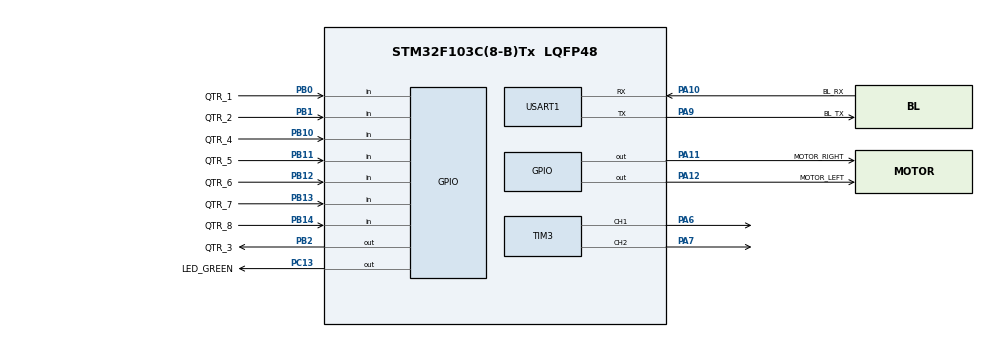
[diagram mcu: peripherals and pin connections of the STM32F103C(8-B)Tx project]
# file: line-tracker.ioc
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Mcu.Family=STM32F1
Mcu.Name=STM32F103C(8-B)Tx
Mcu.Package=LQFP48
NVIC.PriorityGroup=NVIC_PRIORITYGROUP_4
NVIC.TIM2_IRQn=true\:0\:0\:false\:false\:true\:true\:true
PA10.GPIO_Label=BL_RX
PA10.Mode=Asynchronous
PA10.Signal=USART1_RX
PA11.GPIO_Label=MOTOR_RIGHT
PA11.Signal=GPIO_Output
PA12.GPIO_Label=MOTOR_LEFT
PA12.Signal=GPIO_Output
PA13.Mode=Serial_Wire
PA13.Signal=SYS_JTMS-SWDIO
PA14.Mode=Serial_Wire
PA14.Signal=SYS_JTCK-SWCLK
PA6.Signal=S_TIM3_CH1
PA7.Signal=S_TIM3_CH2
PA9.GPIO_Label=BL_TX
PA9.Mode=Asynchronous
PA9.Signal=USART1_TX
PB0.GPIO_Label=QTR_1
PB0.Signal=GPIO_Input
PB1.GPIO_Label=QTR_2
PB1.Signal=GPIO_Input
PB10.GPIO_Label=QTR_4
PB10.Signal=GPIO_Input
PB11.GPIO_Label=QTR_5
PB11.Signal=GPIO_Input
PB12.GPIO_Label=QTR_6
PB12.Signal=GPIO_Input
PB13.GPIO_Label=QTR_7
PB13.Signal=GPIO_Input
PB14.GPIO_Label=QTR_8
PB14.Signal=GPIO_Input
PB2.GPIO_Label=QTR_3
PB2.Signal=GPIO_Output
PC13-TAMPER-RTC.GPIO_Label=LED_GREEN
PC13-TAMPER-RTC.Signal=GPIO_Output
PC14-OSC32_IN.Mode=LSE-External-Oscillator
PC14-OSC32_IN.Signal=RCC_OSC32_IN
PC15-OSC32_OUT.Mode=LSE-External-Oscillator
PC15-OSC32_OUT.Signal=RCC_OSC32_OUT
PD0-OSC_IN.Mode=HSE-External-Oscillator
PD0-OSC_IN.Signal=RCC_OSC_IN
PD1-OSC_OUT.Mode=HSE-External-Oscillator
PD1-OSC_OUT.Signal=RCC_OSC_OUT
ProjectManager.HeapSize=0x0
ProjectManager.StackSize=0x400
ProjectManager.TargetToolchain=TrueSTUDIO
RCC.AHBFreq_Value=72000000
RCC.APB1CLKDivider=RCC_HCLK_DIV2
RCC.APB1Freq_Value=36000000
RCC.APB1TimFreq_Value=72000000
RCC.APB2Freq_Value=72000000
RCC.APB2TimFreq_Value=72000000
RCC.HCLKFreq_Value=72000000
RCC.PLLMUL=RCC_PLL_MUL9
RCC.PLLSourceVirtual=RCC_PLLSOURCE_HSE
RCC.SYSCLKFreq_VALUE=72000000
RCC.SYSCLKSource=RCC_SYSCLKSOURCE_PLLCLK
RCC.USBFreq_Value=72000000
SH.S_TIM3_CH1.0=TIM3_CH1,PWM Generation1 CH1
SH.S_TIM3_CH2.0=TIM3_CH2,PWM Generation2 CH2
TIM2.Period=2
TIM2.Prescaler=23
TIM3.Channel-PWM\ Generation1\ CH1=TIM_CHANNEL_1
TIM3.Channel-PWM\ Generation2\ CH2=TIM_CHANNEL_2
USART1.VirtualMode=VM_ASYNC
VP_TIM2_VS_ClockSourceINT.Mode=Internal
board=custom

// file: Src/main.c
/* USER CODE BEGIN Header */
/**
  ******************************************************************************
  * @file           : main.c
  * @brief          : Main program body
  ******************************************************************************
  * @attention
  *
  * <h2><center>&copy; Copyright (c) 2019 STMicroelectronics.
  * All rights reserved.</center></h2>
  *
  * This software component is licensed by ST under BSD 3-Clause license,
  * the "License"; You may not use this file except in compliance with the
  * License. You may obtain a copy of the License at:
  *                        opensource.org/licenses/BSD-3-Clause
  *
  ******************************************************************************
  */
/* USER CODE END Header */

#include "main.h"
#include "tim.h"
#include "usart.h"
#include "gpio.h"

/* USER CODE BEGIN Includes */
#include "dwt_stm32_delay.h"
/* USER CODE END Includes */

void SystemClock_Config(void);

int main(void)
{

  /* MCU Configuration--------------------------------------------------------*/

  /* Reset of all peripherals, Initializes the Flash interface and the Systick. */

  LL_APB2_GRP1_EnableClock(LL_APB2_GRP1_PERIPH_AFIO);
  LL_APB1_GRP1_EnableClock(LL_APB1_GRP1_PERIPH_PWR);

  NVIC_SetPriorityGrouping(NVIC_PRIORITYGROUP_4);

  /* System interrupt init*/

  /** NOJTAG: JTAG-DP Disabled and SW-DP Enabled
  */
  LL_GPIO_AF_Remap_SWJ_NOJTAG();

  /* Configure the system clock */
  SystemClock_Config();

  /* Initialize all configured peripherals */
  MX_GPIO_Init();
  MX_TIM2_Init();
  MX_TIM3_Init();
  MX_USART1_UART_Init();
  /* USER CODE BEGIN 2 */
  DWT_Delay_Init();
  __enable_irq();
  /* USER CODE END 2 */

  /* Infinite loop */
  while (1)
  {

    /* USER CODE BEGIN 3 */
	  LL_GPIO_TogglePin(LED_GREEN_GPIO_Port,LED_GREEN_Pin);
	  LL_mDelay(1000);
	  DWT_Delay_us(10);
  }
  /* USER CODE END 3 */
}

void SystemClock_Config(void)
{
  LL_FLASH_SetLatency(LL_FLASH_LATENCY_2);

   if(LL_FLASH_GetLatency() != LL_FLASH_LATENCY_2)
  {
    Error_Handler();
  }
  LL_RCC_HSE_Enable();

   /* Wait till HSE is ready */
  while(LL_RCC_HSE_IsReady() != 1)
  {

  }
  LL_RCC_PLL_ConfigDomain_SYS(LL_RCC_PLLSOURCE_HSE_DIV_1, LL_RCC_PLL_MUL_9);
  LL_RCC_PLL_Enable();

   /* Wait till PLL is ready */
  while(LL_RCC_PLL_IsReady() != 1)
  {

  }
  LL_RCC_SetAHBPrescaler(LL_RCC_SYSCLK_DIV_1);
  LL_RCC_SetAPB1Prescaler(LL_RCC_APB1_DIV_2);
  LL_RCC_SetAPB2Prescaler(LL_RCC_APB2_DIV_1);
  LL_RCC_SetSysClkSource(LL_RCC_SYS_CLKSOURCE_PLL);

   /* Wait till System clock is ready */
  while(LL_RCC_GetSysClkSource() != LL_RCC_SYS_CLKSOURCE_STATUS_PLL)
  {

  }
  LL_Init1msTick(72000000);
  LL_SYSTICK_SetClkSource(LL_SYSTICK_CLKSOURCE_HCLK);
  LL_SetSystemCoreClock(72000000);
}

void Error_Handler(void)
{
}

/************************ (C) COPYRIGHT STMicroelectronics *****END OF FILE****/
